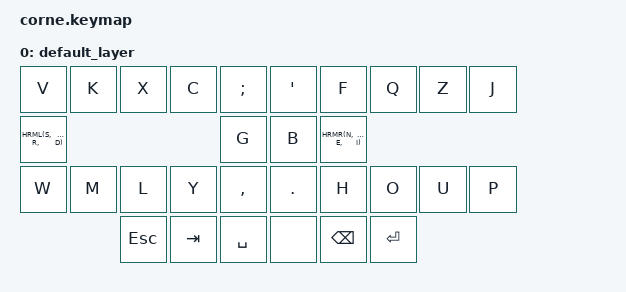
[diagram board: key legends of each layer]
#include <behaviors.dtsi>
#include <dt-bindings/zmk/keys.h>
#include <dt-bindings/zmk/bt.h>
#include <dt-bindings/zmk/outputs.h>

// layers
#define DEF     0
#define NUM     1
#define NAV     2
#define MEDIA   3
#define FUN     4

#include "keys/36.h"
#include "includes/macros.dtsi"
#include "includes/combos.dtsi"
#include "includes/behaviors.dtsi"

// ╰─────────┼─────────┼─────────┼─────────┼─────────┤   ├─────────┼─────────┼─────────┼─────────┼─────────╯
//                     │SEC THMB │PRM THMB │TER THMB │   │TER THMB │PRM THMB │SEC THMB │
//                     │   MED   │  NUM    │ LSHIFT  │   │  NAV    │CTRL+DEL │  FUN    │
//                     │ Sk SHFT │ REPEAT  │  Tab    │   │  SPACE  │  DEL    │ SK CTRL │
//                     ╰─────────────────────────────╯   ╰─────────────────────────────╯
//                          ╰caps_word on double tap, not sure if I like it yet

// // Layer switching
// #define SECLTHMB  &ltsk  MEDIA    LSHIFT  // tap for sticky shift : hold for media layer
// #define PRMLTHMB  &ltr   NUM      0      //  zero here because key-repeat does not take arguments
// #define TERLTHMB  &mt    LSHIFT   TAB   //   tap for tab : hold for shift

// #define TERRTHMB  &lt    NAV      SPACE
// #define PRMRTHMB  &mt    RC(BSPC) BSPC   // tap gives you backspace : long tap gives you delete word
// #define SECRTHMB  &ltsk  FUN      RCTRL //  tap for sticky ctrl : hold for function layer

// // shorter codes
// #define BPSTE    &kp  K_PASTE
// #define BCPY     &kp  K_COPY
// #define BCUT     &kp  K_CUT
// #define BUNDO    &kp  K_UNDO
// #define BREDO    &kp  K_REDO
// #define BPREV    &kp  K_PREV
// #define BNEXT    &kp  K_NEXT
// #define BPLYPSE  &kp  K_PP
// #define BMUTE    &kp  K_MUTE
// #define BSTOP    &kp  K_STOP2
// #define BVOLD    &kp  K_VOL_DN
// #define BVOLU    &kp  K_VOL_UP
// #define OUTTOG   &out OUT_TOG // toggle keyboard output bluetooth/usb
// #define ___      &trans      //  transparent
// #define _x_      &none

// Home row mods
#define HRML(k1, k2, k3, k4) &hml LSHFT k1 &hml LCTRL k2 &hml LALT  k3 &hml LGUI  k4
#define HRMR(k1, k2, k3, k4) &hmr RGUI  k1 &hmr RALT  k2 &hmr RCTRL k3 &hmr RSHFT k4

/ {
  chosen {
    zmk,matrix_transform = &five_column_transform;
  };
};

/ {
  keymap {
    compatible = "zmk,keymap";
    default_layer { // layer 0 (default)
      bindings = <
// ╭─────────────────────────────────────────────────╮   ╭─────────────────────────────────────────────────╮
// │    V    │    K    │    X    │    C    │    SEMI │   │    SQT  │    F    │    Q    │    Z    │    J    │
    &kp V     &kp K     &kp X     &kp C     &kp SEMI      &kp SQT   &kp F     &kp Q     &kp Z     &kp J
// ├─────────┼─────────┼─────────┼─────────┼─────────┤   ├─────────┼─────────┼─────────┼─────────┼─────────┤
// │    S    │    T    │    R    │    D    │    G    │   │    B    │    N    │    A    │    E    │    I    │
    HRML(S,       T,        R,        D)    &kp G         &kp B     HRMR(N,       A,        E,       I)
// ├─────────┼─────────┼─────────┼─────────┼─────────┤   ├─────────┼─────────┼─────────┼─────────┼─────────┤
// │    W    │    M    │    L    │    Y    │   COMMA │   │    DOT  │    H    │    O    │    U    │    P    │
    &kp W     &kp M     &kp L     &kp Y    &kp COMMA      &kp DOT   &kp H     &kp O     &kp U     &kp P
// ╰─────────┼─────────┼─────────┼─────────┼─────────┤   ├─────────┼─────────┼─────────┼─────────┼─────────╯
                        &kp ESC   &kp TAB  &kp SPACE      &none     &kp BSPC  &kp RET
//                     ╰─────────────────────────────╯   ╰─────────────────────────────╯
      >;
    };
//     symbol_layer { // layer 1 (numbers)
//       bindings = <
// // ╭─────────────────────────────────────────────────╮   ╭─────────────────────────────────────────────────╮
// // │    1    │    2    │    3    │    4    │    5    │   │    6    │    7    │    8    │    9    │    0    │
//     &kp KP_N1 &kp KP_N2 &kp KP_N3     &kp C     &kp SEMI      &kp SQT   &kp F     &kp Q     &kp Z     &kp J
// // ├─────────┼─────────┼─────────┼─────────┼─────────┤   ├─────────┼─────────┼─────────┼─────────┼─────────┤
// // │    S    │    T    │    R    │    D    │    G    │   │    B    │    N    │    A    │    E    │    I    │
//     HRML(S,       T,        R,        D)    &kp G         &kp B     HRMR(N,       A,        E,       I)
// // ├─────────┼─────────┼─────────┼─────────┼─────────┤   ├─────────┼─────────┼─────────┼─────────┼─────────┤
// // │    W    │    M    │    L    │    Y    │   COMMA │   │    DOT  │    H    │    O    │    U    │    P    │
//     &kp W     &kp M     &kp L     &kp Y    &kp COMMA      &kp DOT   &kp H     &kp O     &kp U     &kp P
// // ╰─────────┼─────────┼─────────┼─────────┼─────────┤   ├─────────┼─────────┼─────────┼─────────┼─────────╯
//                         &kp ESC   &kp TAB  &kp SPACE      &none     &kp BSPC  &kp RET
// //                     ╰─────────────────────────────╯   ╰─────────────────────────────╯
//       >;
//     };

  };
};

